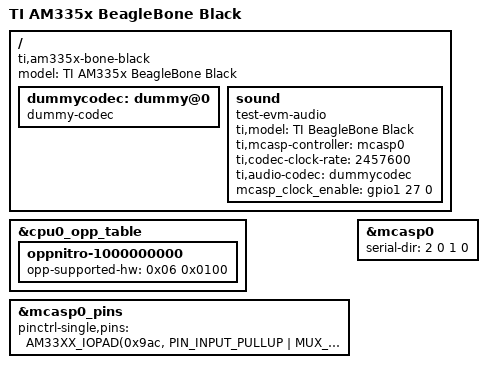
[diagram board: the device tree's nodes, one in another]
/*
 * Copyright (C) 2012 Texas Instruments Incorporated - http://www.ti.com/
 *
 * This program is free software; you can redistribute it and/or modify
 * it under the terms of the GNU General Public License version 2 as
 * published by the Free Software Foundation.
 */
/dts-v1/;

#include "am33xx.dtsi"
#include "am335x-bone-common.dtsi"
#include "am335x-boneblack-common.dtsi"

/ {
	model = "TI AM335x BeagleBone Black";
	compatible = "ti,am335x-bone-black", "ti,am335x-bone", "ti,am33xx";

	dummycodec: dummy@0 {
		#sound-dai-cells = <0>;
		compatible = "dummy-codec";
		status = "okay";
	};
	sound {
		compatible = "test-evm-audio";
		ti,model = "TI BeagleBone Black";
		ti,mcasp-controller = <&mcasp0>;
		ti,codec-clock-rate = <2457600>;
		ti,audio-codec = <&dummycodec>;
		mcasp_clock_enable = <&gpio1 27 0>; /* BeagleBone Black Clk enable on GPIO1_27 */
	  };
};

&cpu0_opp_table {
	/*
	 * All PG 2.0 silicon may not support 1GHz but some of the early
	 * BeagleBone Blacks have PG 2.0 silicon which is guaranteed
	 * to support 1GHz OPP so enable it for PG 2.0 on this board.
	 */
	oppnitro-1000000000 {
		opp-supported-hw = <0x06 0x0100>;
	};
};

&mcasp0_pins {
	pinctrl-single,pins = <
			AM33XX_IOPAD(0x9ac, PIN_INPUT_PULLUP | MUX_MODE0) /* mcasp0_ahcklx.mcasp0_ahclkx */
			AM33XX_IOPAD(0x99c, PIN_OUTPUT_PULLDOWN | MUX_MODE2) /* mcasp0_ahclkr.mcasp0_axr2*/
			AM33XX_IOPAD(0x998, PIN_INPUT_PULLUP | MUX_MODE0) /* Added for RX */
			AM33XX_IOPAD(0x994, PIN_OUTPUT_PULLUP | MUX_MODE0) /* mcasp0_fsx.mcasp0_fsx */
			AM33XX_IOPAD(0x990, PIN_OUTPUT_PULLDOWN | MUX_MODE0) /* mcasp0_aclkx.mcasp0_aclkx */
			AM33XX_IOPAD(0x86c, PIN_OUTPUT_PULLDOWN | MUX_MODE7) /* gpmc_a11.GPIO1_27 */
		>;
};

&mcasp0 {
	serial-dir = <2 0 1 0>;
};
